# MKM34Z7 register map
Vendor: Freescale Semiconductor, Inc.; Series: Kinetis_M; File version: 1.6
CPU: CM0PLUS r0p0, little endian, no MPU, no FPU, VTOR, 2 interrupt priority bits
Registers are 32-bit, read-write, reset 0x0 unless marked. A register's access mark holds for its fields unless they carry their own. Offsets are from the block's base; [hi:lo] are bit positions; {n}, {i} and the like mark numbered series; 'fields as' and 'values as' point back to an identical list.

## XBAR — Crossbar Switch
Base 0x40055000; register names take the prefix XBAR_
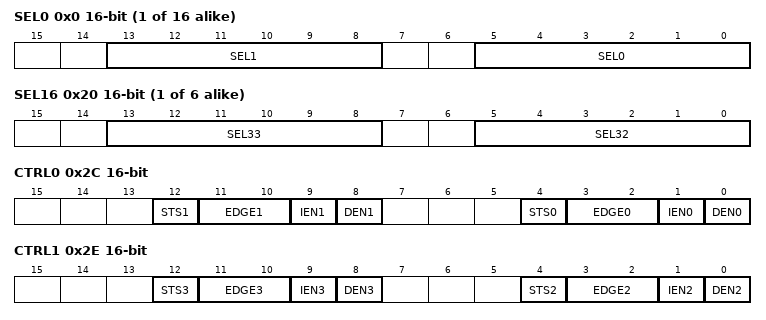
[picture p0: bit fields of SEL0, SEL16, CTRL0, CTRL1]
{0x0+2i} SEL{i} 16-bit (i=0..15) — Crossbar Select Register {i}
  [13:8] SEL{2i+1} — Input (XBAR_INn) to be muxed to XBAR_OUT{2i+1} (refer to Functional Description section for input/output assignment)
    0=Logic 1 (VDD); 1=Logic 0 (VSS); 2=AFE modulator clock output; 3=AFE modulator 0 data output; 4=LPTimer Output; 5=Clock Output; {v}=Quad Timer channel {v-6} output (v=6..9); 10=iRTC Clock Output; 11=CMP0 Output; 12=CMP1 Output; 13=iRTC Alarm Output; 14=UART TX Output (after modulation); 15=EWM Output (EWM_OUT); 16=PIT 0 Timer Interrupt Flag 0 (Timeout 0); {v}=XBAR Input pin {v-17} (v=17..25); 26=ORed conversion complete flag for all SAR ADC channels; 27=ORed conversion complete flag for all AFE channels; {v}=AFE Channel {v-28} conversion complete (v=28..31); 32=DMA Done Signal; 33=XBAR Input pin 9; 34=XBAR Input pin 10; 35=CMP2 Output; 36=PIT 0 Timer Interrupt Flag 1 (Timeout 1); 37=PIT 1 Timer Interrupt Flag 0 (Timeout 0); 38=PIT 1 Timer Interrupt Flag 1 (Timeout 1); 39=AFE modulator 1 data output; 40=AFE modulator 2 data output; 41=AFE modulator 3 data output; 42=SAR ADC conversion complete A; 43=SAR ADC conversion complete B; 44=SAR ADC conversion complete C; 45=SAR ADC conversion complete D; {v}=PDB0 CH0 Pre-trigger {v-46} (v=46..49); 50=PDB0 CH0 Trigger; 51=PDB0 Pulse-Out 0
  [5:0] SEL{2i} — Input (XBAR_INn) to be muxed to XBAR_OUT{2i} (refer to Functional Description section for input/output assignment)
    values as SEL{2i+1}
{0x0+2i} SEL{i} 16-bit (i=16..21) — Crossbar Select Register {i}
  [13:8] SEL{2i+1} — Input (XBAR_INn) to be muxed to XBAR_OUT{2i+1}
    values as SEL0.SEL{2i+1}
  [5:0] SEL{2i} — Input (XBAR_INn) to be muxed to XBAR_OUT{2i}
    values as SEL0.SEL{2i+1}
0x2C CTRL0 16-bit — Crossbar Control Register 0
  [12] STS1 — Edge detection status for XBAR_OUT1
    0=Active edge not yet detected on XBAR_OUT1; 1=Active edge detected on XBAR_OUT1
  [11:10] EDGE1 — Active edge for edge detection on XBAR_OUT1
    0=STS1 never asserts; 1=STS1 asserts on rising edges of XBAR_OUT1; 2=STS1 asserts on falling edges of XBAR_OUT1; 3=STS1 asserts on rising and falling edges of XBAR_OUT1
  [9] IEN1 — Interrupt Enable for XBAR_OUT1
    0=Interrupt disabled; 1=Interrupt enabled
  [8] DEN1 — DMA Enable for XBAR_OUT1
    0=DMA disabled; 1=DMA enabled
  [4] STS0 — Edge detection status for XBAR_OUT0
    0=Active edge not yet detected on XBAR_OUT0; 1=Active edge detected on XBAR_OUT0
  [3:2] EDGE0 — Active edge for edge detection on XBAR_OUT0
    0=STS0 never asserts; 1=STS0 asserts on rising edges of XBAR_OUT0; 2=STS0 asserts on falling edges of XBAR_OUT0; 3=STS0 asserts on rising and falling edges of XBAR_OUT0
  [1] IEN0 — Interrupt Enable for XBAR_OUT0
    0=Interrupt disabled; 1=Interrupt enabled
  [0] DEN0 — DMA Enable for XBAR_OUT0
    0=DMA disabled; 1=DMA enabled
0x2E CTRL1 16-bit — Crossbar Control Register 1
  [12] STS3 — Edge detection status for XBAR_OUT3
    0=Active edge not yet detected on XBAR_OUT3; 1=Active edge detected on XBAR_OUT3
  [11:10] EDGE3 — Active edge for edge detection on XBAR_OUT3
    0=STS3 never asserts; 1=STS3 asserts on rising edges of XBAR_OUT3; 2=STS3 asserts on falling edges of XBAR_OUT3; 3=STS3 asserts on rising and falling edges of XBAR_OUT3
  [9] IEN3 — Interrupt Enable for XBAR_OUT3
    0=Interrupt disabled; 1=Interrupt enabled
  [8] DEN3 — DMA Enable for XBAR_OUT3
    0=DMA disabled; 1=DMA enabled
  [4] STS2 — Edge detection status for XBAR_OUT2
    0=Active edge not yet detected on XBAR_OUT2; 1=Active edge detected on XBAR_OUT2
  [3:2] EDGE2 — Active edge for edge detection on XBAR_OUT2
    0=STS2 never asserts; 1=STS2 asserts on rising edges of XBAR_OUT2; 2=STS2 asserts on falling edges of XBAR_OUT2; 3=STS2 asserts on rising and falling edges of XBAR_OUT2
  [1] IEN2 — Interrupt Enable for XBAR_OUT2
    0=Interrupt disabled; 1=Interrupt enabled
  [0] DEN2 — DMA Enable for XBAR_OUT2
    0=DMA disabled; 1=DMA enabled
